# PIC18F56Q24 register map
Vendor: Microchip
Registers are 8-bit, read-write, reset 0x0 unless marked. A register's access mark holds for its fields unless they carry their own. Addresses are absolute, and some are shared; only a register's first bit layout is shown; [hi:lo] are bit positions; {n}, {i} and the like mark numbered series.

## amp_fvr_ts_ctrl
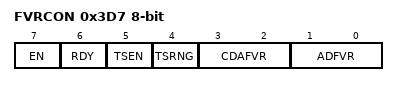
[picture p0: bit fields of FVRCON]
0x3D7 FVRCON reset not defined — (power-on value xx000000)
  [7] EN — Zero-Cross Detect Software Enable bit
  [6] RDY ro
  [5] TSEN — Zero-Cross Detect Data Output
  [4] TSRNG — Zero-Cross Detect Polarity bit
  [3:2] CDAFVR
  [1:0] ADFVR — Zero-Cross Detect Positive-going Edge Interrupt Enable

## DOS_xxxxx_port_control
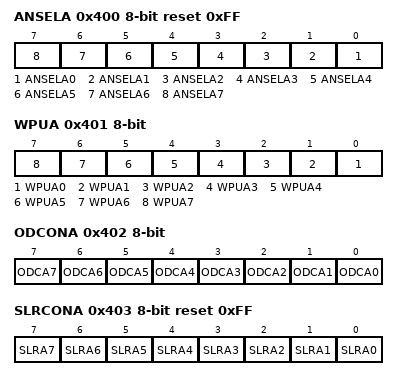
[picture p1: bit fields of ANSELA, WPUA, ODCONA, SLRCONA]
0x400 ANSELA reset 0xFF
  [n] ANSELA{n} (n=0..7)
0x401 WPUA
  [n] WPUA{n} (n=0..7)
0x402 ODCONA
  [n] ODCA{n} (n=0..7)
0x403 SLRCONA reset 0xFF
  [n] SLRA{n} (n=0..7)
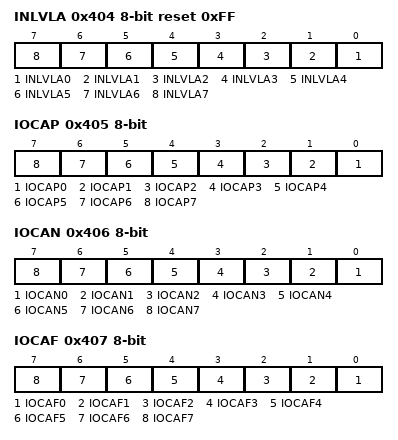
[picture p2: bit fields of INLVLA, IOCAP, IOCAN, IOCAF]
0x404 INLVLA reset 0xFF
  [n] INLVLA{n} (n=0..7)
0x405 IOCAP
  [n] IOCAP{n} (n=0..7)
0x406 IOCAN
  [n] IOCAN{n} (n=0..7)
0x407 IOCAF
  [n] IOCAF{n} (n=0..7)
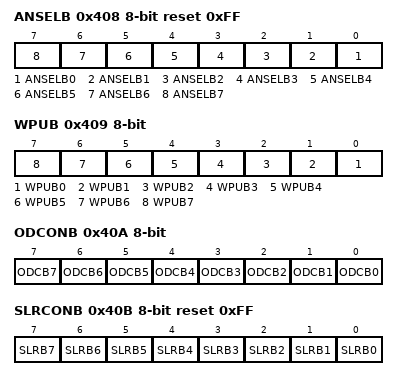
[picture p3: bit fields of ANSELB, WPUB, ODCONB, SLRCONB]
0x408 ANSELB reset 0xFF
  [n] ANSELB{n} (n=0..7)
0x409 WPUB
  [n] WPUB{n} (n=0..7)
0x40A ODCONB
  [n] ODCB{n} (n=0..7)
0x40B SLRCONB reset 0xFF
  [n] SLRB{n} (n=0..7)
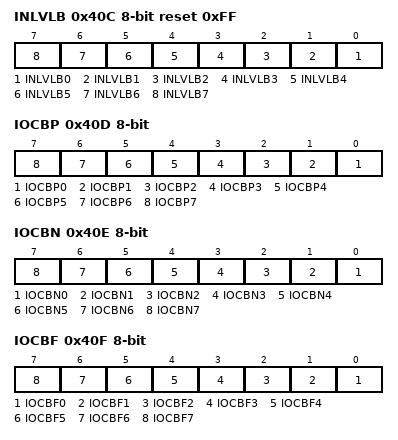
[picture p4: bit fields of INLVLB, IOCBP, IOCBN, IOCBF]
0x40C INLVLB reset 0xFF
  [n] INLVLB{n} (n=0..7)
0x40D IOCBP
  [n] IOCBP{n} (n=0..7)
0x40E IOCBN
  [n] IOCBN{n} (n=0..7)
0x40F IOCBF
  [n] IOCBF{n} (n=0..7)
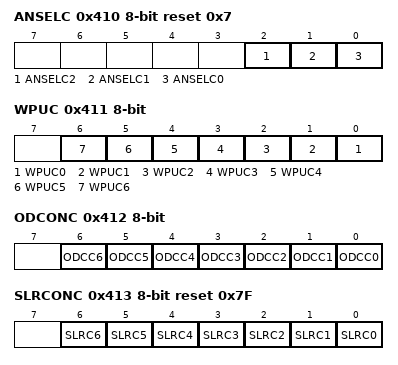
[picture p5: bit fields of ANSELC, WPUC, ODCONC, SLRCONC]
0x410 ANSELC reset 0x7
  [2] ANSELC2, [1] ANSELC1, [0] ANSELC0
0x411 WPUC
  [n] WPUC{n} (n=0..6)
0x412 ODCONC
  [n] ODCC{n} (n=0..6)
0x413 SLRCONC reset 0x7F
  [n] SLRC{n} (n=0..6)
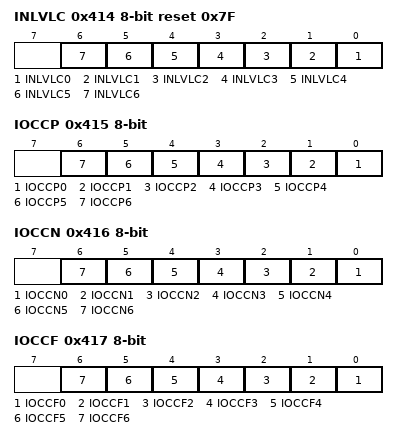
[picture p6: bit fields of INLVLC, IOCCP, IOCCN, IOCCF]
0x414 INLVLC reset 0x7F
  [n] INLVLC{n} (n=0..6)
0x415 IOCCP
  [n] IOCCP{n} (n=0..6)
0x416 IOCCN
  [n] IOCCN{n} (n=0..6)
0x417 IOCCF
  [n] IOCCF{n} (n=0..6)
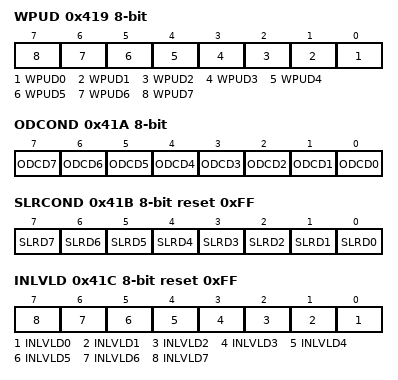
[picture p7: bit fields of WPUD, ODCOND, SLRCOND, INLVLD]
0x419 WPUD
  [n] WPUD{n} (n=0..7)
0x41A ODCOND
  [n] ODCD{n} (n=0..7)
0x41B SLRCOND reset 0xFF
  [n] SLRD{n} (n=0..7)
0x41C INLVLD reset 0xFF
  [n] INLVLD{n} (n=0..7)
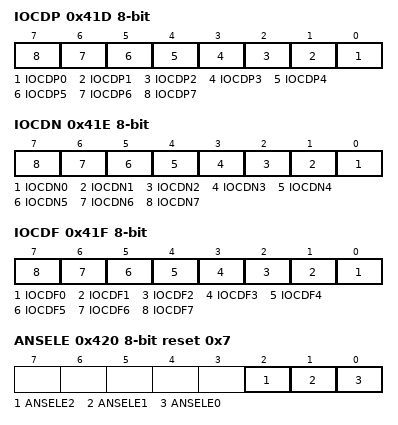
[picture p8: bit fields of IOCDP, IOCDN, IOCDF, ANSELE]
0x41D IOCDP
  [n] IOCDP{n} (n=0..7)
0x41E IOCDN
  [n] IOCDN{n} (n=0..7)
0x41F IOCDF
  [n] IOCDF{n} (n=0..7)
0x420 ANSELE reset 0x7
  [2] ANSELE2, [1] ANSELE1, [0] ANSELE0
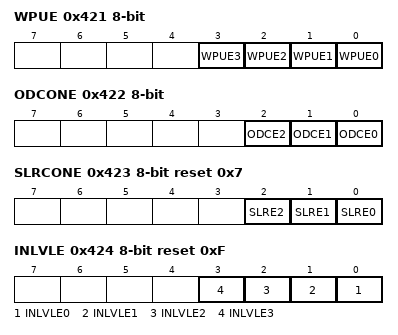
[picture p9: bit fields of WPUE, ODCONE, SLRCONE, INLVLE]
0x421 WPUE
  [n] WPUE{n} (n=0..3)
0x422 ODCONE
  [2] ODCE2, [1] ODCE1, [0] ODCE0
0x423 SLRCONE reset 0x7
  [2] SLRE2, [1] SLRE1, [0] SLRE0
0x424 INLVLE reset 0xF
  [n] INLVLE{n} (n=0..3)
0x425 IOCEP
  [3] IOCEP3
0x426 IOCEN
  [3] IOCEN3
0x427 IOCEF
  [3] IOCEF3
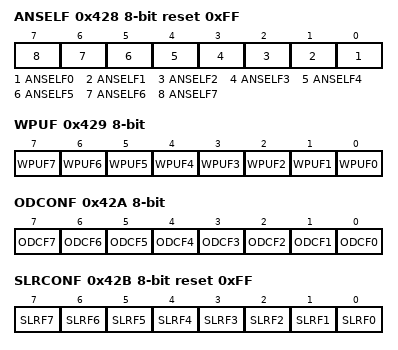
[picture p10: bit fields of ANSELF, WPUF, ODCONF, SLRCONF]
0x428 ANSELF reset 0xFF
  [n] ANSELF{n} (n=0..7)
0x429 WPUF
  [n] WPUF{n} (n=0..7)
0x42A ODCONF
  [n] ODCF{n} (n=0..7)
0x42B SLRCONF reset 0xFF
  [n] SLRF{n} (n=0..7)
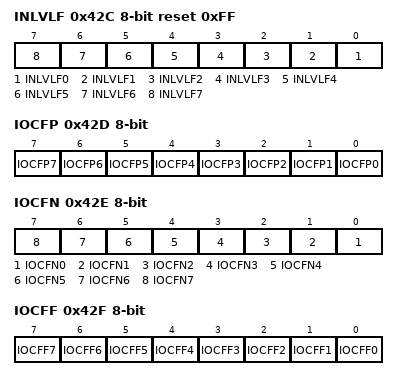
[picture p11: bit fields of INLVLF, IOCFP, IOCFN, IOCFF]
0x42C INLVLF reset 0xFF
  [n] INLVLF{n} (n=0..7)
0x42D IOCFP
  [n] IOCFP{n} (n=0..7)
0x42E IOCFN
  [n] IOCFN{n} (n=0..7)
0x42F IOCFF
  [n] IOCFF{n} (n=0..7)
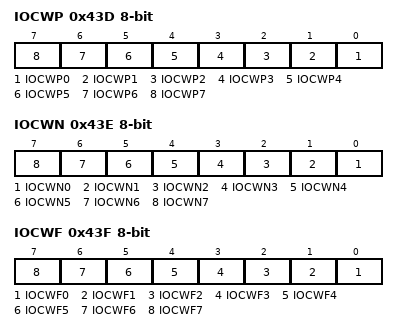
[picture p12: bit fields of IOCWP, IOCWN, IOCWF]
0x43D IOCWP
  [n] IOCWP{n} (n=0..7)
0x43E IOCWN
  [n] IOCWN{n} (n=0..7)
0x43F IOCWF
  [n] IOCWF{n} (n=0..7)

## tmr_dds
0x440 NCO1ACCL
  [7:0] ACC
0x441 NCO1ACCH
  [7:0] ACC
0x442 NCO1ACCU
  [3:0] ACC
0x443 NCO1INCL reset 0x1
  [7:0] INC
0x444 NCO1INCH
  [7:0] INC
0x445 NCO1INCU
  [3:0] INC
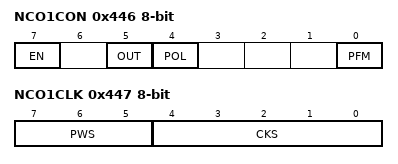
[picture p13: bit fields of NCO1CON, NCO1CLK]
0x446 NCO1CON — Configurable logic cell control
  [7] EN, [5] OUT ro, [4] POL, [0] PFM
0x447 NCO1CLK
  [7:5] PWS, [4:0] CKS

## int
0x459 IVTLOCK
  [0] IVTLOCKED
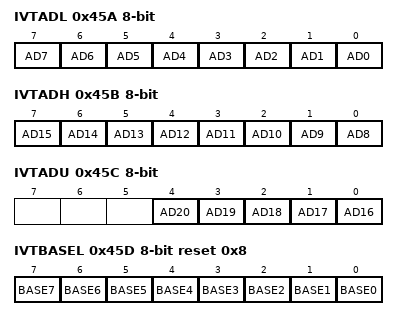
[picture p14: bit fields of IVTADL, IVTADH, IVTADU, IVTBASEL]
0x45A IVTADL
  [n] AD{n} (n=0..7)
0x45B IVTADH
  [n-8] AD{n} (n=8..15)
0x45C IVTADU
  [n-16] AD{n} (n=16..20)
0x45D IVTBASEL reset 0x8
  [n] BASE{n} (n=0..7)
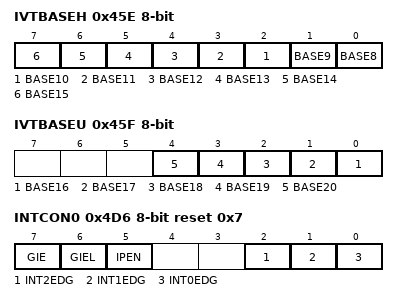
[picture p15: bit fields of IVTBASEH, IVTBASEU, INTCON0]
0x45E IVTBASEH
  [n-8] BASE{n} (n=8..15)
0x45F IVTBASEU
  [n-16] BASE{n} (n=16..20)
0x4D6 INTCON0 reset 0x7
  [7] GIE, [6] GIEL, [5] IPEN, [2] INT2EDG, [1] INT1EDG, [0] INT0EDG
0x4D7 INTCON1 ro
  [7:6] STAT

## pwm_cmp
0x460 PWM1ERS
  [3:0] ERS
0x461 PWM1CLK
  [4:0] CLK
0x462 PWM1LDS
  [3:0] LDS
{0x454+0xF*i} PWM{i}PRL (i=1..3)
  [7:0] PRL
{0x455+0xF*i} PWM{i}PRH (i=1..3)
  [7:0] PRH
{0x456+0xF*i} PWM{i}CPRE (i=1..3)
  [7:0] CPRE
{0x457+0xF*i} PWM{i}PIPOS (i=1..3)
  [7:0] PIPOS
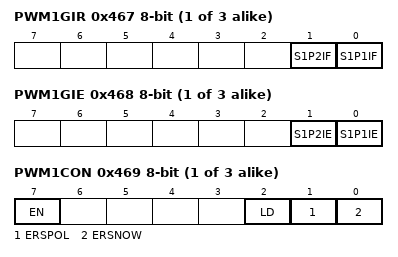
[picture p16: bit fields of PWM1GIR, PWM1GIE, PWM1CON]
{0x458+0xF*i} PWM{i}GIR (i=1..3)
  [1] S1P2IF, [0] S1P1IF
{0x459+0xF*i} PWM{i}GIE (i=1..3)
  [1] S1P2IE, [0] S1P1IE
{0x45A+0xF*i} PWM{i}CON (i=1..3)
  [7] EN, [2] LD, [1] ERSPOL, [0] ERSNOW
{0x45B+0xF*i} PWM{i}S1CFG (i=1..3)
  [7] POL2, [6] POL1, [3] PPEN, [2:0] MODE
{0x45C+0xF*i} PWM{i}S1P1L (i=1..3)
  [7:0] S1P1L
{0x45D+0xF*i} PWM{i}S1P1H (i=1..3)
  [7:0] S1P1H
{0x45E+0xF*i} PWM{i}S1P2L (i=1..3)
  [7:0] S1P2L
{0x45F+0xF*i} PWM{i}S1P2H (i=1..3)
  [7:0] S1P2H
0x46F PWM2ERS
  [7:0] ERS
0x470 PWM2CLK
  [7:0] CLK
0x471 PWM2LDS
  [7:0] LDS
0x47E PWM3ERS
  [7:0] ERS
0x47F PWM3CLK
  [7:0] CLK
0x480 PWM3LDS
  [7:0] LDS
